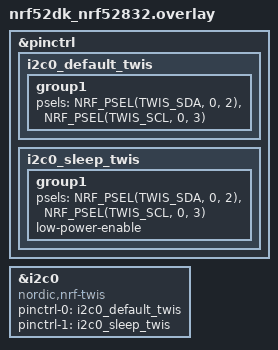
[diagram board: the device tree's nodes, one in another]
/*
 * i2c0 as an I2C target (TWIS) on P0.02 (SDA) and P0.03 (SCL).
 * Wiring: P0.02 to zbook I2C_SDA, P0.03 to zbook I2C_SCL (header H1), common GND.
 */

&pinctrl {
	i2c0_default_twis: i2c0_default_twis {
		group1 {
			psels = <NRF_PSEL(TWIS_SDA, 0, 2)>,
				<NRF_PSEL(TWIS_SCL, 0, 3)>;
		};
	};

	i2c0_sleep_twis: i2c0_sleep_twis {
		group1 {
			psels = <NRF_PSEL(TWIS_SDA, 0, 2)>,
				<NRF_PSEL(TWIS_SCL, 0, 3)>;
			low-power-enable;
		};
	};
};

&i2c0 {
	compatible = "nordic,nrf-twis";
	status = "okay";
	pinctrl-0 = <&i2c0_default_twis>;
	pinctrl-1 = <&i2c0_sleep_twis>;
	pinctrl-names = "default", "sleep";
};
